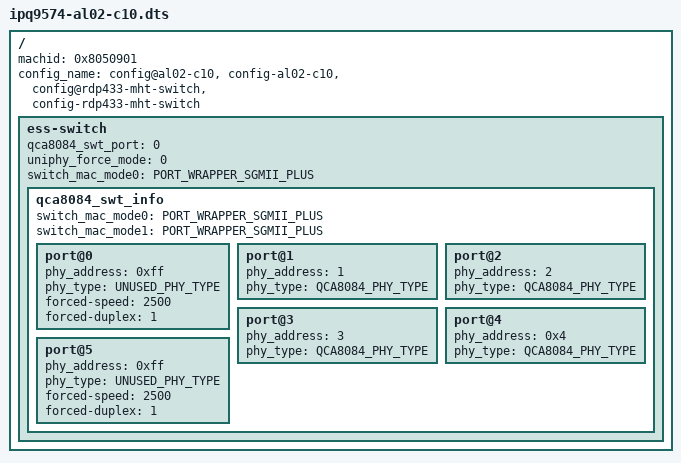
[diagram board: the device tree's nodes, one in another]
/*
 * Copyright (c) 2016-2021, The Linux Foundation. All rights reserved.
 * Copyright (c) 2022 Qualcomm Innovation Center, Inc. All rights reserved.
 *
 * This program is free software; you can redistribute it and/or modify
 * it under the terms of the GNU General Public License version 2 and
 * only version 2 as published by the Free Software Foundation.
 *
 * This program is distributed in the hope that it will be useful,
 * but WITHOUT ANY WARRANTY; without even the implied warranty of
 * MERCHANTABILITY or FITNESS FOR A PARTICULAR PURPOSE.  See the
 * GNU General Public License for more details.
 */

/dts-v1/;
#include "ipq9574-al02-c8.dts"
/ {
	machid = <0x8050901>;
	config_name = "config@al02-c10", "config-al02-c10", "config@rdp433-mht-switch", "config-rdp433-mht-switch";

	ess-switch {
		/* Overriding config to support QCA8084 Switch instead of
		 * QCA8084 PHY
		 */
		qca8084_swt_port = <0>;
		uniphy_force_mode = <0>;
		switch_mac_mode0 = <PORT_WRAPPER_SGMII_PLUS>;

		qca8084_swt_info {
			switch_mac_mode0 = <PORT_WRAPPER_SGMII_PLUS>;
			switch_mac_mode1 = <PORT_WRAPPER_SGMII_PLUS>;

			port@0 {
				phy_address = <0xff>;
				phy_type = <UNUSED_PHY_TYPE>;
				forced-speed = <2500>;
				forced-duplex = <1>;
			};
			port@1 {
				phy_address = <1>;
				phy_type = <QCA8084_PHY_TYPE>;
			};
			port@2 {
				phy_address = <2>;
				phy_type = <QCA8084_PHY_TYPE>;
			};
			port@3 {
				phy_address = <3>;
				phy_type = <QCA8084_PHY_TYPE>;
			};
			port@4 {
				phy_address = <0x4>;
				phy_type = <QCA8084_PHY_TYPE>;
			};
			port@5 {
				phy_address = <0xff>;
				phy_type = <UNUSED_PHY_TYPE>;
				forced-speed = <2500>;
				forced-duplex = <1>;
			};
		};
	};
};
